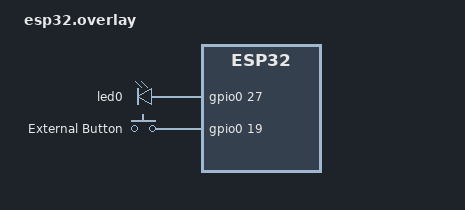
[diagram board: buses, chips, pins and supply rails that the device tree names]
/ {
    aliases {
        led = &led0;
        sw = &switch0;
    };

    leds {
        compatible = "gpio-leds";

        led0: led {
            gpios = <&gpio0 27 GPIO_ACTIVE_HIGH>;
        };
    };

    switches {
        compatible = "gpio-keys";

        switch0: switch {
            gpios = <&gpio0 19 GPIO_ACTIVE_HIGH>;
            label = "External Button";
        };
    };
};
